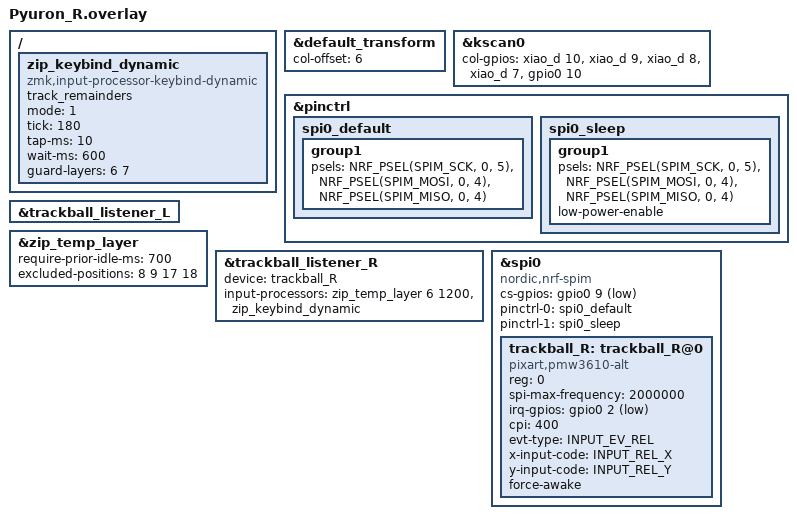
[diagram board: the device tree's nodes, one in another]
#include <zephyr/dt-bindings/input/input-event-codes.h>
#include "Pyuron.dtsi"
// NOTE: keys.h must be included AFTER Pyuron.dtsi. Pyuron.dtsi pulls in the
// matrix-transform RC(row,col) macro; keys.h's RC(code) modifier must be the
// last definition so the keymap's RC(TAB) resolves to right-control (1 arg).
#include <behaviors.dtsi>
#include <dt-bindings/zmk/keys.h>
#include <dt-bindings/zmk/pointing.h>

&default_transform {
    col-offset = <6>;
};

&kscan0 {
    col-gpios = <&xiao_d 10 GPIO_ACTIVE_HIGH>,
                <&xiao_d 9 GPIO_ACTIVE_HIGH>,
                <&xiao_d 8 GPIO_ACTIVE_HIGH>,
                <&xiao_d 7 GPIO_ACTIVE_HIGH>,
                <&gpio0 10 GPIO_ACTIVE_HIGH>;
};

&pinctrl {
    spi0_default: spi0_default {
        group1 {
            psels = <NRF_PSEL(SPIM_SCK, 0, 5)>,
                    <NRF_PSEL(SPIM_MOSI, 0, 4)>,
                    <NRF_PSEL(SPIM_MISO, 0, 4)>;
        };
    };

    spi0_sleep: spi0_sleep {
        group1 {
            psels = <NRF_PSEL(SPIM_SCK, 0, 5)>,
                    <NRF_PSEL(SPIM_MOSI, 0, 4)>,
                    <NRF_PSEL(SPIM_MISO, 0, 4)>;
            low-power-enable;
        };
    };
};

&trackball_listener_L {
    status = "okay";
};

// zip_temp_layer: activate MOUSE layer (6) on trackball move.
// NOTE: timeout param is milliseconds. "500" means 0.5s.
// 固着時の切り分けのため、誤発火を減らして滞在時間を伸ばす。
&zip_temp_layer {
    require-prior-idle-ms = <700>;
    // 8=O(MOUSE層MB3/ズームCtrl), 9=P(GEST3) を除外
    excluded-positions = <8 9 17 18>;
};

&trackball_listener_R {
    status = "okay";
    device = <&trackball_R>;

    // Normal: cursor movement + auto-activate MOUSE layer (6)
    // then pass through the dynamic gesture processor.
    // zip_keybind_dynamic intercepts on layers that have bindings configured
    // (via RPC at runtime); all other layers pass through to cursor as usual.
    input-processors = <&zip_temp_layer 6 1200>, <&zip_keybind_dynamic>;

    // Layer 7 (hyphen-hold) uses the native smooth 2D scroller defined in
    // Pyuron.dtsi (no override here). Ball motion maps proportionally to wheel
    // scroll (trackpad-like), Ctrl+scroll zoom works, no cursor leak.
    // guard-layers = <6 7> in zip_keybind_dynamic ensures layers 6 and 7
    // are always passed through even if accidentally configured.
};

/ {
    // Dynamic layer-aware gesture processor.
    // Bindings are configured at runtime via the ZMK Studio RPC (no reflash
    // needed after the initial flash of this firmware).
    // guard-layers: layers 6 (MOUSE auto) and 7 (scroller) always pass through.
    zip_keybind_dynamic: zip_keybind_dynamic {
        compatible = "zmk,input-processor-keybind-dynamic";
        #input-processor-cells = <0>;
        track_remainders;
        mode = <1>;
        tick = <180>;
        tap-ms = <10>;
        wait-ms = <600>;
        guard-layers = <6 7>;
    };
};

&spi0 {
    status = "okay";
    cs-gpios = <&gpio0 9 GPIO_ACTIVE_LOW>;
    pinctrl-0 = <&spi0_default>;
    pinctrl-1 = <&spi0_sleep>;
    pinctrl-names = "default", "sleep";
    compatible = "nordic,nrf-spim";

    trackball_R: trackball_R@0 {
        status = "okay";
        compatible = "pixart,pmw3610-alt";
        reg = <0>;
        spi-max-frequency = <2000000>;
        irq-gpios = <&gpio0 2 (GPIO_ACTIVE_LOW | GPIO_PULL_UP)>;
        cpi = <400>;
        evt-type = <INPUT_EV_REL>;
        x-input-code = <INPUT_REL_X>;
        y-input-code = <INPUT_REL_Y>;
        force-awake;
    };
};
